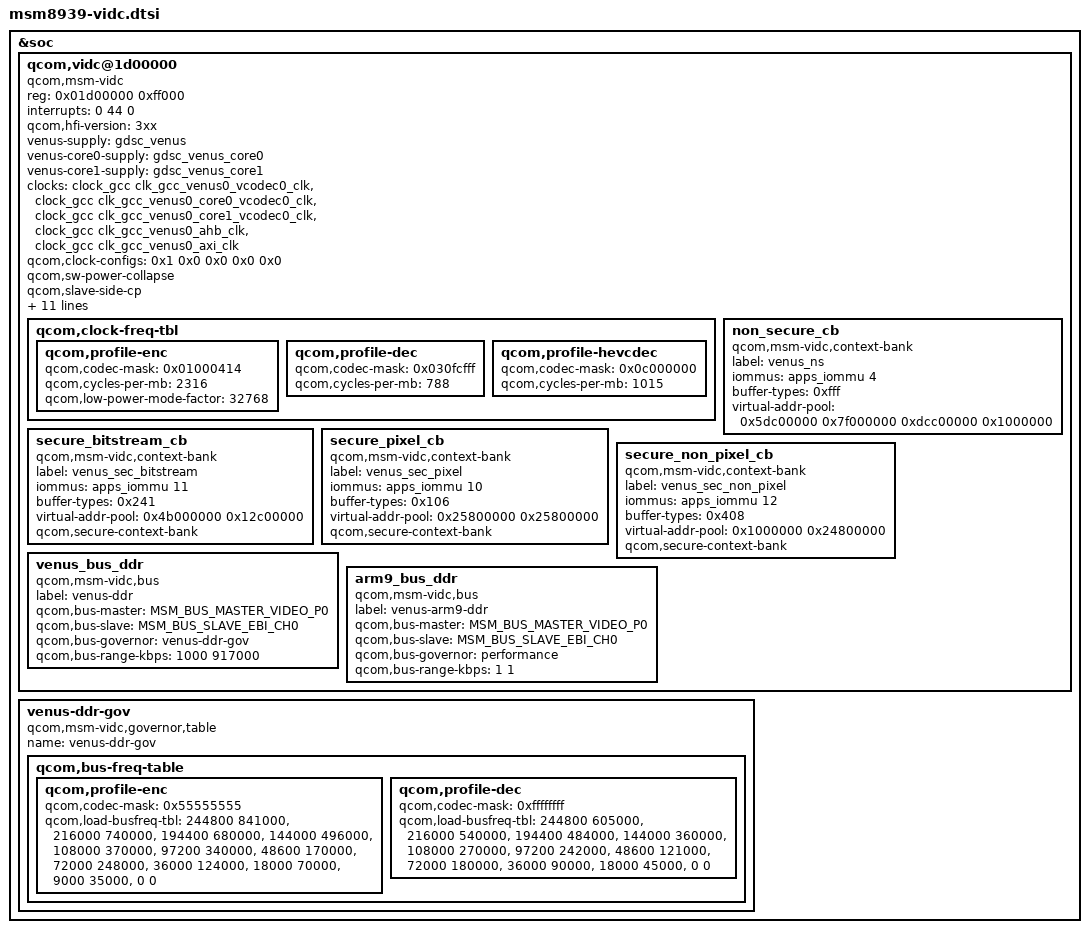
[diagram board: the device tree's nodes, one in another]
/* Copyright (c) 2018, The Linux Foundation. All rights reserved.
 * Copyright (c) 2018, Pavel Dubrova <pashadubrova@gmail.com>
 *
 * This program is free software; you can redistribute it and/or modify
 * it under the terms of the GNU General Public License version 2 and
 * only version 2 as published by the Free Software Foundation.
 *
 * This program is distributed in the hope that it will be useful,
 * but WITHOUT ANY WARRANTY; without even the implied warranty of
 * MERCHANTABILITY or FITNESS FOR A PARTICULAR PURPOSE.  See the
 * GNU General Public License for more details.
 */

&soc {
	qcom,vidc@1d00000 {
		compatible = "qcom,msm-vidc";
		reg = <0x01d00000 0xff000>;
		interrupts = <0 44 0>;
		qcom,hfi-version = "3xx";
		venus-supply = <&gdsc_venus>;
		venus-core0-supply = <&gdsc_venus_core0>;
		venus-core1-supply = <&gdsc_venus_core1>;
		clocks = <&clock_gcc clk_gcc_venus0_vcodec0_clk>,
			<&clock_gcc clk_gcc_venus0_core0_vcodec0_clk>,
			<&clock_gcc clk_gcc_venus0_core1_vcodec0_clk>,
			<&clock_gcc clk_gcc_venus0_ahb_clk>,
			<&clock_gcc clk_gcc_venus0_axi_clk>;
		clock-names = "core_clk", "core0_clk", "core1_clk", "iface_clk", "bus_clk";
		qcom,clock-configs = <0x1 0x0 0x0 0x0 0x0>;
		qcom,sw-power-collapse;
		qcom,slave-side-cp;
		qcom,hfi = "venus";
		qcom,reg-presets = <0xe0020 0x0aaaaaaa>,
			<0xe0024 0x0aaaaaaa>,
			<0x80124 0x00000003>;
		qcom,qdss-presets = <0x825000 0x1000>,
			<0x826000 0x1000>,
			<0x821000 0x1000>,
			<0x802000 0x1000>,
			<0x9180000 0x1000>,
			<0x9181000 0x1000>;
		qcom,max-hw-load = <489600>; /* 1080p @ 30 + 1080p @ 30 */
		qcom,firmware-name = "venus";
		qcom,allowed-clock-rates = <266670000 133330000 200000000 133330000>;
		qcom,clock-freq-tbl {
			qcom,profile-enc {
				qcom,codec-mask = <0x01000414>;
				qcom,cycles-per-mb = <2316>;
				qcom,low-power-mode-factor = <32768>;
			};
			qcom,profile-dec {
				qcom,codec-mask = <0x030fcfff>;
				qcom,cycles-per-mb = <788>;
			};
			qcom,profile-hevcdec {
				qcom,codec-mask = <0x0c000000>;
				qcom,cycles-per-mb = <1015>;
			};
		};

		/* IOMMUs */
		/*
		 * non-secure addr pool from 1500 MB to 3532 MB
		 *                           3532 MB to 3548 MB
		 */
		non_secure_cb {
			compatible = "qcom,msm-vidc,context-bank";
			label = "venus_ns";
			iommus = <&apps_iommu 4>;
			buffer-types = <0xfff>;
			virtual-addr-pool = <0x5dc00000 0x7f000000
						0xdcc00000 0x1000000>;
		};

		/* secure bitstream addr pool from 1200 MB to 1500 MB */
		secure_bitstream_cb {
			compatible = "qcom,msm-vidc,context-bank";
			label = "venus_sec_bitstream";
			iommus = <&apps_iommu 11>;
			buffer-types = <0x241>;
			virtual-addr-pool = <0x4b000000 0x12c00000>;
			qcom,secure-context-bank;
		};

		/* secure pixel addr pool from 616 MB to 1200 MB */
		secure_pixel_cb {
			compatible = "qcom,msm-vidc,context-bank";
			label = "venus_sec_pixel";
			iommus = <&apps_iommu 10>;
			buffer-types = <0x106>;
			virtual-addr-pool = <0x25800000 0x25800000>;
			qcom,secure-context-bank;
		};

		/* secure non-pixel addr pool from 16 MB to 616 MB */
		secure_non_pixel_cb {
			compatible = "qcom,msm-vidc,context-bank";
			label = "venus_sec_non_pixel";
			iommus = <&apps_iommu 12>;
			buffer-types = <0x408>;
			virtual-addr-pool = <0x1000000 0x24800000>;
			qcom,secure-context-bank;
		};

		/* Buses */
		venus_bus_ddr {
			compatible = "qcom,msm-vidc,bus";
			label = "venus-ddr";
			qcom,bus-master = <MSM_BUS_MASTER_VIDEO_P0>;
			qcom,bus-slave = <MSM_BUS_SLAVE_EBI_CH0>;
			qcom,bus-governor = "venus-ddr-gov";
			qcom,bus-range-kbps = <1000 917000>;
		};

		arm9_bus_ddr {
			compatible = "qcom,msm-vidc,bus";
			label = "venus-arm9-ddr";
			qcom,bus-master = <MSM_BUS_MASTER_VIDEO_P0>;
			qcom,bus-slave = <MSM_BUS_SLAVE_EBI_CH0>;
			qcom,bus-governor = "performance";
			qcom,bus-range-kbps = <1 1>;
		};
	};

	venus-ddr-gov {
		compatible = "qcom,msm-vidc,governor,table";
		name = "venus-ddr-gov";
		status = "ok";
		qcom,bus-freq-table {
			qcom,profile-enc {
				qcom,codec-mask = <0x55555555>;
				qcom,load-busfreq-tbl =
					<244800 841000>,   /* 1080p30E   */
					<216000 740000>,   /* 720p60E    */
					<194400 680000>,   /* FWVGA120E  */
					<144000 496000>,   /* VGA120E    */
					<108000 370000>,   /* 720p30E    */
					<97200  340000>,   /* FWVGA60E   */
					<48600  170000>,   /* FWVGA30E   */
					<72000  248000>,   /* VGA60E     */
					<36000  124000>,   /* VGA30E     */
					<18000  70000>,    /* QVGA60E    */
					<9000   35000>,    /* QVGA30E    */
					<0      0>;
			};
			qcom,profile-dec {
				qcom,codec-mask = <0xffffffff>;
				qcom,load-busfreq-tbl =
					<244800 605000>,   /* 1080p30D   */
					<216000 540000>,   /* 720p60D    */
					<194400 484000>,   /* FWVGA120D  */
					<144000 360000>,   /* VGA120D    */
					<108000 270000>,   /* 720p30D    */
					<97200  242000>,   /* FWVGA60D   */
					<48600  121000>,   /* FWVGA30D   */
					<72000  180000>,   /* VGA60D     */
					<36000  90000>,    /* VGA30D     */
					<18000  45000>,    /* HVGA30D    */
					<0      0>;
			};
		};
	};
};
